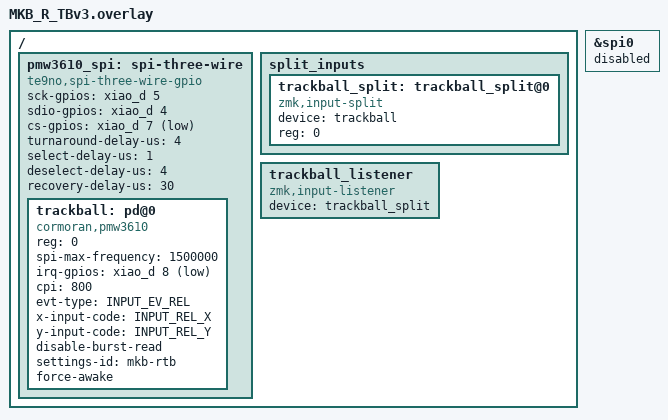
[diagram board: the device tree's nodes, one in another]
/*input-split*/
/ {
	pmw3610_spi: spi-three-wire {
		compatible = "te9no,spi-three-wire-gpio";
		status = "okay";
		#address-cells = <1>;
		#size-cells = <0>;

		/* MKB right TBv3 wiring: SCK=P0.05 (D5), shared SDIO=P0.04 (D4). */
		sck-gpios = <&xiao_d 5 GPIO_ACTIVE_HIGH>;
		sdio-gpios = <&xiao_d 4 GPIO_ACTIVE_HIGH>;
		cs-gpios = <&xiao_d 7 GPIO_ACTIVE_LOW>;

		turnaround-delay-us = <4>;
		select-delay-us = <1>;
		deselect-delay-us = <4>;
		recovery-delay-us = <30>;

		trackball: pd@0 {
			status = "okay";
			compatible = "cormoran,pmw3610";
			reg = <0>;
			spi-max-frequency = <1500000>;
			irq-gpios = <&xiao_d 8 (GPIO_ACTIVE_LOW | GPIO_PULL_UP)>;
			cpi = <800>;
			evt-type = <INPUT_EV_REL>;
			x-input-code = <INPUT_REL_X>;
			y-input-code = <INPUT_REL_Y>;
			disable-burst-read;
			settings-id = "mkb-rtb";
			force-awake;
		};
	};

	split_inputs {
        #address-cells = <1>;
        #size-cells = <0>;

        trackball_split: trackball_split@0 {
            compatible = "zmk,input-split";
            status = "okay";
            device = <&trackball>;
            reg = <0>;
        };
    };

    trackball_listener: trackball_listener {
        compatible = "zmk,input-listener";
        status = "okay";
        device = <&trackball_split>;
    };

};

&spi0 {
	status = "disabled";
};
